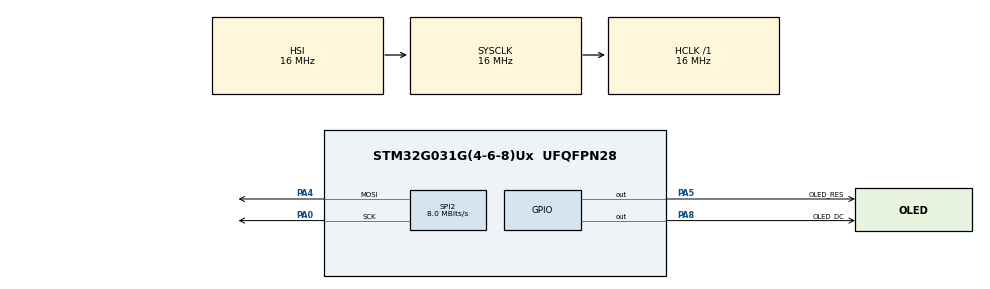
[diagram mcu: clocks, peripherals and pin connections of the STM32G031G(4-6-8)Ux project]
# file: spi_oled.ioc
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Mcu.Family=STM32G0
Mcu.Name=STM32G031G(4-6-8)Ux
Mcu.Package=UFQFPN28
PA0.GPIO_Speed=GPIO_SPEED_FREQ_VERY_HIGH
PA0.Mode=TX_Only_Simplex_Unidirect_Master
PA0.Signal=SPI2_SCK
PA4.GPIO_Speed=GPIO_SPEED_FREQ_VERY_HIGH
PA4.Mode=TX_Only_Simplex_Unidirect_Master
PA4.Signal=SPI2_MOSI
PA5.GPIO_Label=OLED_RES
PA5.GPIO_Speed=GPIO_SPEED_FREQ_HIGH
PA5.Signal=GPIO_Output
PA8.GPIO_Label=OLED_DC
PA8.GPIO_Speed=GPIO_SPEED_FREQ_HIGH
PA8.Signal=GPIO_Output
ProjectManager.HeapSize=0x200
ProjectManager.StackSize=0x400
ProjectManager.TargetToolchain=STM32CubeIDE
RCC.AHBFreq_Value=16000000
RCC.CortexFreq_Value=16000000
RCC.EXTERNAL_CLOCK_VALUE=12288000
RCC.HCLKFreq_Value=16000000
RCC.HSE_VALUE=8000000
RCC.HSI_VALUE=16000000
RCC.LSE_VALUE=32768
RCC.SYSCLKFreq_VALUE=16000000
RCC.VCOOutputFreq_Value=128000000
SPI2.CalculateBaudRate=8.0 MBits/s
SPI2.Direction=SPI_DIRECTION_2LINES
SPI2.Mode=SPI_MODE_MASTER
SPI2.VirtualType=VM_MASTER
board=custom

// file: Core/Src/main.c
/* USER CODE BEGIN Header */
/**
  ******************************************************************************
  * @file           : main.c
  * @brief          : Main program body
  ******************************************************************************
  * @attention
  *
  * Copyright (c) 2023 STMicroelectronics.
  * All rights reserved.
  *
  * This software is licensed under terms that can be found in the LICENSE file
  * in the root directory of this software component.
  * If no LICENSE file comes with this software, it is provided AS-IS.
  *
  ******************************************************************************
  */
/* USER CODE END Header */
#include "main.h"
#include "oled.h"

SPI_HandleTypeDef hspi2;

void SystemClock_Config(void);
static void MX_GPIO_Init(void);
static void MX_SPI2_Init(void);

int main(void)
{

  /* MCU Configuration--------------------------------------------------------*/

  /* Reset of all peripherals, Initializes the Flash interface and the Systick. */
  HAL_Init();

  /* Configure the system clock */
  SystemClock_Config();

  /* Initialize all configured peripherals */
  MX_GPIO_Init();
  MX_SPI2_Init();
  /* USER CODE BEGIN 2 */
  OLED_Init();
  OLED_ShowString(10, 10, "STM32G031", 8, 0);
  OLED_ShowString(20, 20, "STM32G031", 8, 1);
  OLED_Refresh();
  /* USER CODE END 2 */

  /* Infinite loop */
  while (1)
  {

  }
}

void SystemClock_Config(void)
{
  RCC_OscInitTypeDef RCC_OscInitStruct = {0};
  RCC_ClkInitTypeDef RCC_ClkInitStruct = {0};

  /** Configure the main internal regulator output voltage
  */
  HAL_PWREx_ControlVoltageScaling(PWR_REGULATOR_VOLTAGE_SCALE1);

  /** Initializes the RCC Oscillators according to the specified parameters
  * in the RCC_OscInitTypeDef structure.
  */
  RCC_OscInitStruct.OscillatorType = RCC_OSCILLATORTYPE_HSI;
  RCC_OscInitStruct.HSIState = RCC_HSI_ON;
  RCC_OscInitStruct.HSIDiv = RCC_HSI_DIV1;
  RCC_OscInitStruct.HSICalibrationValue = RCC_HSICALIBRATION_DEFAULT;
  RCC_OscInitStruct.PLL.PLLState = RCC_PLL_NONE;
  if (HAL_RCC_OscConfig(&RCC_OscInitStruct) != HAL_OK)
  {
    Error_Handler();
  }

  /** Initializes the CPU, AHB and APB buses clocks
  */
  RCC_ClkInitStruct.ClockType = RCC_CLOCKTYPE_HCLK|RCC_CLOCKTYPE_SYSCLK
                              |RCC_CLOCKTYPE_PCLK1;
  RCC_ClkInitStruct.SYSCLKSource = RCC_SYSCLKSOURCE_HSI;
  RCC_ClkInitStruct.AHBCLKDivider = RCC_SYSCLK_DIV1;
  RCC_ClkInitStruct.APB1CLKDivider = RCC_HCLK_DIV1;

  if (HAL_RCC_ClockConfig(&RCC_ClkInitStruct, FLASH_LATENCY_0) != HAL_OK)
  {
    Error_Handler();
  }
}

static void MX_SPI2_Init(void)
{

  /* SPI2 parameter configuration*/
  hspi2.Instance = SPI2;
  hspi2.Init.Mode = SPI_MODE_MASTER;
  hspi2.Init.Direction = SPI_DIRECTION_2LINES;
  hspi2.Init.DataSize = SPI_DATASIZE_8BIT;
  hspi2.Init.CLKPolarity = SPI_POLARITY_LOW;
  hspi2.Init.CLKPhase = SPI_PHASE_1EDGE;
  hspi2.Init.NSS = SPI_NSS_SOFT;
  hspi2.Init.BaudRatePrescaler = SPI_BAUDRATEPRESCALER_2;
  hspi2.Init.FirstBit = SPI_FIRSTBIT_MSB;
  hspi2.Init.TIMode = SPI_TIMODE_DISABLE;
  hspi2.Init.CRCCalculation = SPI_CRCCALCULATION_DISABLE;
  hspi2.Init.CRCPolynomial = 7;
  hspi2.Init.CRCLength = SPI_CRC_LENGTH_DATASIZE;
  hspi2.Init.NSSPMode = SPI_NSS_PULSE_ENABLE;
  if (HAL_SPI_Init(&hspi2) != HAL_OK)
  {
    Error_Handler();
  }

}

static void MX_GPIO_Init(void)
{
  GPIO_InitTypeDef GPIO_InitStruct = {0};

  /* GPIO Ports Clock Enable */
  __HAL_RCC_GPIOA_CLK_ENABLE();

  /*Configure GPIO pin Output Level */
  HAL_GPIO_WritePin(GPIOA, OLED_RES_Pin|OLED_DC_Pin, GPIO_PIN_RESET);

  /*Configure GPIO pins : OLED_RES_Pin OLED_DC_Pin */
  GPIO_InitStruct.Pin = OLED_RES_Pin|OLED_DC_Pin;
  GPIO_InitStruct.Mode = GPIO_MODE_OUTPUT_PP;
  GPIO_InitStruct.Pull = GPIO_NOPULL;
  GPIO_InitStruct.Speed = GPIO_SPEED_FREQ_HIGH;
  HAL_GPIO_Init(GPIOA, &GPIO_InitStruct);

}

void Error_Handler(void)
{
  __disable_irq();
  while (1)
  {
  }
}
